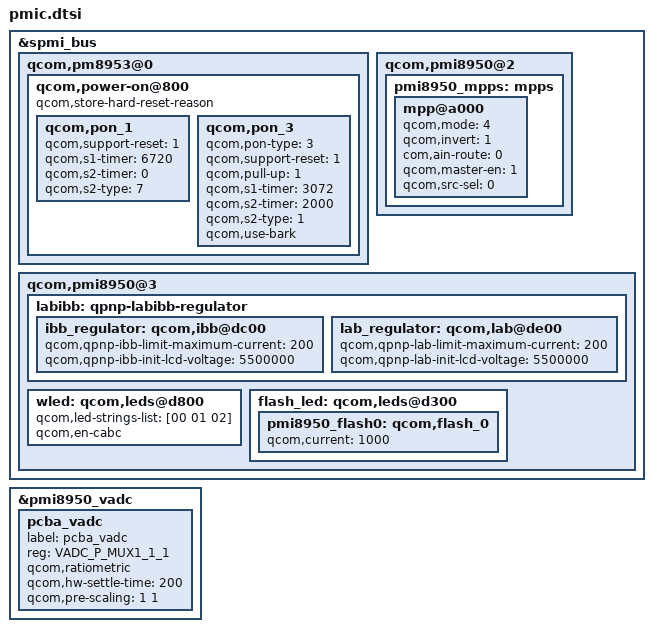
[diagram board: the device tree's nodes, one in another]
/* msm-pm8953 */
&spmi_bus {
	qcom,pm8953@0 {
		qcom,power-on@800 {
			qcom,store-hard-reset-reason;
			qcom,pon_1 {
				qcom,support-reset = <1>;
				qcom,s1-timer = <6720>;
				qcom,s2-timer = <0>;
				qcom,s2-type = <7>;
			};

			qcom,pon_3 {
				qcom,pon-type = <3>;
				qcom,support-reset = <1>;
				qcom,pull-up = <1>;
				qcom,s1-timer = <3072>;
				qcom,s2-timer = <2000>;
				qcom,s2-type = <1>;
				qcom,use-bark;
			};
		};
		/delete-node/ qcom,pm8953_typec@bf00;
	};
};

&pmi8950_vadc {
	pcba_vadc {
		label = "pcba_vadc";
		reg = <VADC_P_MUX1_1_1>;
		qcom,ratiometric;
		qcom,hw-settle-time = <200>;
		qcom,pre-scaling = <1 1>;
	};
};

&spmi_bus {
	qcom,pmi8950@2 {
		pmi8950_mpps: mpps {
			mpp@a000 {
				qcom,mode = <4>; /* AIN input */
				qcom,invert = <1>; /* Enable MPP */
				com,ain-route = <0>; /* AMUX 5 */
				qcom,master-en = <1>;
				qcom,src-sel = <0>; /* Function constant */
				status = "okay";
			};
		};
	};
	qcom,pmi8950@3 {
		labibb: qpnp-labibb-regulator {
			status = "ok";
			ibb_regulator: qcom,ibb@dc00 {
				qcom,qpnp-ibb-limit-maximum-current = <200>;
				qcom,qpnp-ibb-init-lcd-voltage = <5500000>;
			};
			lab_regulator: qcom,lab@de00 {
				qcom,qpnp-lab-limit-maximum-current = <200>;
				qcom,qpnp-lab-init-lcd-voltage = <5500000>;
			};
		};
		wled: qcom,leds@d800 {
			qcom,led-strings-list = [00 01 02];
			qcom,en-cabc;
		};
		flash_led: qcom,leds@d300 {
			pmi8950_flash0: qcom,flash_0 {
				qcom,current = <1000>;
			};
		};
	};
};
